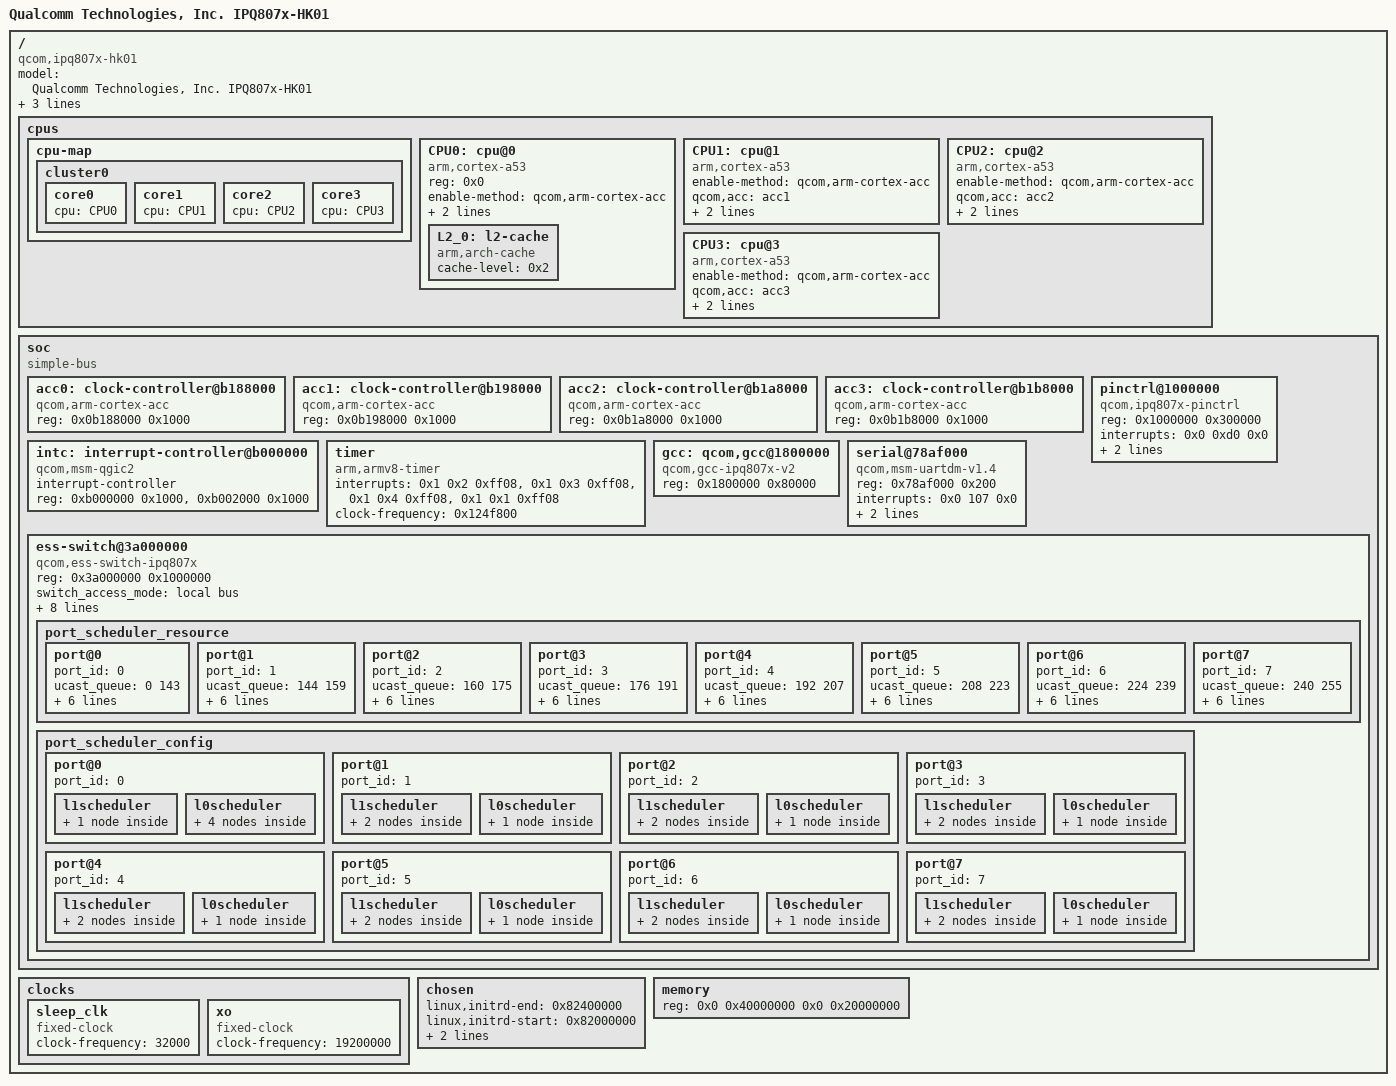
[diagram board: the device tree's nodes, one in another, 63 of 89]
/dts-v1/;
/*
 * Copyright (c) 2016-2018, The Linux Foundation. All rights reserved.
 *
 * Permission to use, copy, modify, and/or distribute this software for any
 * purpose with or without fee is hereby granted, provided that the above
 * copyright notice and this permission notice appear in all copies.
 *
 * THE SOFTWARE IS PROVIDED "AS IS" AND THE AUTHOR DISCLAIMS ALL WARRANTIES
 * WITH REGARD TO THIS SOFTWARE INCLUDING ALL IMPLIED WARRANTIES OF
 * MERCHANTABILITY AND FITNESS. IN NO EVENT SHALL THE AUTHOR BE LIABLE FOR
 * ANY SPECIAL, DIRECT, INDIRECT, OR CONSEQUENTIAL DAMAGES OR ANY DAMAGES
 * WHATSOEVER RESULTING FROM LOSS OF USE, DATA OR PROFITS, WHETHER IN AN
 * ACTION OF CONTRACT, NEGLIGENCE OR OTHER TORTIOUS ACTION, ARISING OUT OF
 * OR IN CONNECTION WITH THE USE OR PERFORMANCE OF THIS SOFTWARE.
 */

#include <dt-bindings/clock/qcom,gcc-ipq807x.h>
#include <dt-bindings/reset/qcom,gcc-ipq807x.h>

/ {
	#address-cells = <0x2>;
	#size-cells = <0x2>;
	model = "Qualcomm Technologies, Inc. IPQ807x-HK01";
	compatible = "qcom,ipq807x-hk01", "qcom,ipq807x";
	qcom,msm-id = <0x125 0x0>;
	interrupt-parent = <&intc>;
	qcom,board-id = <0x10 0x0>;

	cpus {
		#address-cells = <0x1>;
		#size-cells = <0x0>;

		cpu-map {

			cluster0 {

				core0 {
					cpu = <&CPU0>;
				};

				core1 {
					cpu = <&CPU1>;
				};

				core2 {
					cpu = <&CPU2>;
				};

				core3 {
					cpu = <&CPU3>;
				};
			};

		};

		 CPU0: cpu@0 {
			device_type = "cpu";
			compatible = "arm,cortex-a53";
			reg = <0x0>;
			enable-method = "qcom,arm-cortex-acc";
			qcom,acc = <&acc0>;
			next-level-cache = <&L2_0>;

			L2_0: l2-cache {
				compatible = "arm,arch-cache";
				cache-level = <0x2>;
			};
		};

		 CPU1: cpu@1 {
			device_type = "cpu";
			compatible = "arm,cortex-a53";
			enable-method = "qcom,arm-cortex-acc";
			qcom,acc = <&acc1>;
			reg = <0x1>;
			next-level-cache = <&L2_0>;
		};

		 CPU2: cpu@2 {
			device_type = "cpu";
			compatible = "arm,cortex-a53";
			enable-method = "qcom,arm-cortex-acc";
			qcom,acc = <&acc2>;
			reg = <0x2>;
			next-level-cache = <&L2_0>;
		};

		 CPU3: cpu@3 {
			device_type = "cpu";
			compatible = "arm,cortex-a53";
			enable-method = "qcom,arm-cortex-acc";
			qcom,acc = <&acc3>;
			reg = <0x3>;
			next-level-cache = <&L2_0>;
		};

	};

	soc: soc {
		#address-cells = <0x1>;
		#size-cells = <0x1>;
		ranges = <0 0 0 0xffffffff>;
		compatible = "simple-bus";

		acc0:clock-controller@b188000 {
			compatible = "qcom,arm-cortex-acc";
			reg = <0x0b188000 0x1000>;
		};

		acc1:clock-controller@b198000 {
			compatible = "qcom,arm-cortex-acc";
			reg = <0x0b198000 0x1000>;
		};

		acc2:clock-controller@b1a8000 {
			compatible = "qcom,arm-cortex-acc";
			reg = <0x0b1a8000 0x1000>;
		};

		acc3:clock-controller@b1b8000 {
			compatible = "qcom,arm-cortex-acc";
			reg = <0x0b1b8000 0x1000>;
		};

		pinctrl@1000000 {
			compatible = "qcom,ipq807x-pinctrl";
			reg = <0x1000000 0x300000>;
			interrupts = <0x0 0xd0 0x0>;
			gpio-controller;
			#gpio-cells = <0x2>;
			interrupt-controller;
			#interrupt-cells = <0x2>;
		};

		intc: interrupt-controller@b000000 {
			compatible = "qcom,msm-qgic2";
			interrupt-controller;
			#interrupt-cells = <0x3>;
			reg = <0xb000000 0x1000>,
			<0xb002000 0x1000>;
		};

		timer {
			compatible = "arm,armv8-timer";
			interrupts = <0x1 0x2 0xff08>,
				     <0x1 0x3 0xff08>,
				     <0x1 0x4 0xff08>,
				     <0x1 0x1 0xff08>;
			clock-frequency = <0x124f800>;
		};


		gcc: qcom,gcc@1800000 {
			compatible = "qcom,gcc-ipq807x-v2";
			reg = <0x1800000 0x80000>;
			#clock-cells = <0x1>;
			#reset-cells = <1>;
		};

		serial@78af000 {
			compatible = "qcom,msm-uartdm-v1.4", "qcom,msm-uartdm";
			reg = <0x78af000 0x200>;
			interrupts = <0x0 107 0x0>;
			status = "ok";
			clocks = <&gcc GCC_BLSP1_UART1_APPS_CLK>,
				 <&gcc GCC_BLSP1_AHB_CLK>;
			clock-names = "core", "iface";
		};

		ess-switch@3a000000 {
			compatible = "qcom,ess-switch-ipq807x";
			reg = <0x3a000000 0x1000000>;
			switch_access_mode = "local bus";
			switch_cpu_bmp = <0x1>;  /* cpu port bitmap */
			switch_lan_bmp = <0x3e>; /* lan port bitmap */
			switch_wan_bmp = <0x40>; /* wan port bitmap */
			switch_mac_mode = <0x0>; /* mac mode for uniphy 0*/
			switch_mac_mode1 = <0xff>; /* mac mode for uniphy 1*/
			switch_mac_mode2 = <0xd>; /* mac mode for uniphy 2*/
			bm_tick_mode = <0>; /* bm tick mode */
			tm_tick_mode = <0>; /* tm tick mode */
			port_scheduler_resource {
				port@0 {
					port_id = <0>;
					ucast_queue = <0 143>;
					mcast_queue = <256 271>;
					l0sp = <0 35>;
					l0cdrr = <0 47>;
					l0edrr = <0 47>;
					l1cdrr = <0 7>;
					l1edrr = <0 7>;
				};
				port@1 {
					port_id = <1>;
					ucast_queue = <144 159>;
					mcast_queue = <272 275>;
					l0sp = <36 39>;
					l0cdrr = <48 63>;
					l0edrr = <48 63>;
					l1cdrr = <8 11>;
					l1edrr = <8 11>;
				};
				port@2 {
					port_id = <2>;
					ucast_queue = <160 175>;
					mcast_queue = <276 279>;
					l0sp = <40 43>;
					l0cdrr = <64 79>;
					l0edrr = <64 79>;
					l1cdrr = <12 15>;
					l1edrr = <12 15>;
				};
				port@3 {
					port_id = <3>;
					ucast_queue = <176 191>;
					mcast_queue = <280 283>;
					l0sp = <44 47>;
					l0cdrr = <80 95>;
					l0edrr = <80 95>;
					l1cdrr = <16 19>;
					l1edrr = <16 19>;
				};
				port@4 {
					port_id = <4>;
					ucast_queue = <192 207>;
					mcast_queue = <284 287>;
					l0sp = <48 51>;
					l0cdrr = <96 111>;
					l0edrr = <96 111>;
					l1cdrr = <20 23>;
					l1edrr = <20 23>;
				};
				port@5 {
					port_id = <5>;
					ucast_queue = <208 223>;
					mcast_queue = <288 291>;
					l0sp = <52 55>;
					l0cdrr = <112 127>;
					l0edrr = <112 127>;
					l1cdrr = <24 27>;
					l1edrr = <24 27>;
				};
				port@6 {
					port_id = <6>;
					ucast_queue = <224 239>;
					mcast_queue = <292 295>;
					l0sp = <56 59>;
					l0cdrr = <128 143>;
					l0edrr = <128 143>;
					l1cdrr = <28 31>;
					l1edrr = <28 31>;
				};
				port@7 {
					port_id = <7>;
					ucast_queue = <240 255>;
					mcast_queue = <296 299>;
					l0sp = <60 63>;
					l0cdrr = <144 159>;
					l0edrr = <144 159>;
					l1cdrr = <32 35>;
					l1edrr = <32 35>;
				};
			};
			port_scheduler_config {
				port@0 {
					port_id = <0>;
					l1scheduler {
						group@0 {
							sp = <0 1>; /*L0 SPs*/
							/*cpri cdrr epri edrr*/
							cfg = <0 0 0 0>;
						};
					};
					l0scheduler {
						group@0 {
							/*unicast queues*/
							ucast_queue = <0 4 8>;
							/*multicast queues*/
							mcast_queue = <256 260>;
							/*sp cpricdrrepriedrr*/
							cfg = <0 0 0 0 0>;
						};
						group@1 {
							ucast_queue = <1 5 9>;
							mcast_queue = <257 261>;
							cfg = <0 1 1 1 1>;
						};
						group@2 {
							ucast_queue = <2 6 10>;
							mcast_queue = <258 262>;
							cfg = <0 2 2 2 2>;
						};
						group@3 {
							ucast_queue = <3 7 11>;
							mcast_queue = <259 263>;
							cfg = <0 3 3 3 3>;
						};
					};
				};
				port@1 {
					port_id = <1>;
					l1scheduler {
						group@0 {
							sp = <36>;
							cfg = <0 8 0 8>;
						};
						group@1 {
							sp = <37>;
							cfg = <1 9 1 9>;
						};
					};
					l0scheduler {
						group@0 {
							ucast_queue = <144>;
							ucast_loop_pri = <16>;
							mcast_queue = <272>;
							mcast_loop_pri = <4>;
							cfg = <36 0 48 0 48>;
						};
					};
				};
				port@2 {
					port_id = <2>;
					l1scheduler {
						group@0 {
							sp = <40>;
							cfg = <0 12 0 12>;
						};
						group@1 {
							sp = <41>;
							cfg = <1 13 1 13>;
						};
					};
					l0scheduler {
						group@0 {
							ucast_queue = <160>;
							ucast_loop_pri = <16>;
							mcast_queue = <276>;
							mcast_loop_pri = <4>;
							cfg = <40 0 64 0 64>;
						};
					};
				};
				port@3 {
					port_id = <3>;
					l1scheduler {
						group@0 {
							sp = <44>;
							cfg = <0 16 0 16>;
						};
						group@1 {
							sp = <45>;
							cfg = <1 17 1 17>;
						};
					};
					l0scheduler {
						group@0 {
							ucast_queue = <176>;
							ucast_loop_pri = <16>;
							mcast_queue = <280>;
							mcast_loop_pri = <4>;
							cfg = <44 0 80 0 80>;
						};
					};
				};
				port@4 {
					port_id = <4>;
					l1scheduler {
						group@0 {
							sp = <48>;
							cfg = <0 20 0 20>;
						};
						group@1 {
							sp = <49>;
							cfg = <1 21 1 21>;
						};
					};
					l0scheduler {
						group@0 {
							ucast_queue = <192>;
							ucast_loop_pri = <16>;
							mcast_queue = <284>;
							mcast_loop_pri = <4>;
							cfg = <48 0 96 0 96>;
						};
					};
				};
				port@5 {
					port_id = <5>;
					l1scheduler {
						group@0 {
							sp = <52>;
							cfg = <0 24 0 24>;
						};
						group@1 {
							sp = <53>;
							cfg = <1 25 1 25>;
						};
					};
					l0scheduler {
						group@0 {
							ucast_queue = <208>;
							ucast_loop_pri = <16>;
							mcast_queue = <288>;
							mcast_loop_pri = <4>;
							cfg = <52 0 112 0 112>;
						};
					};
				};
				port@6 {
					port_id = <6>;
					l1scheduler {
						group@0 {
							sp = <56>;
							cfg = <0 28 0 28>;
						};
						group@1 {
							sp = <57>;
							cfg = <1 29 1 29>;
						};
					};
					l0scheduler {
						group@0 {
							ucast_queue = <224>;
							ucast_loop_pri = <16>;
							mcast_queue = <292>;
							mcast_loop_pri = <4>;
							cfg = <56 0 128 0 128>;
						};
					};
				};
				port@7 {
					port_id = <7>;
					l1scheduler {
						group@0 {
							sp = <60>;
							cfg = <0 32 0 32>;
						};
						group@1 {
							sp = <61>;
							cfg = <1 33 1 33>;
						};
					};
					l0scheduler {
						group@0 {
							ucast_queue = <240>;
							ucast_loop_pri = <16>;
							mcast_queue = <296>;
							cfg = <60 0 144 0 144>;
						};
					};
				};
			};
		};

	};

	clocks {
		sleep_clk: sleep_clk {
			compatible = "fixed-clock";
			clock-frequency = <32000>;
			#clock-cells = <0>;
		};

		xo: xo {
			compatible = "fixed-clock";
			clock-frequency = <19200000>;
			#clock-cells = <0>;
		};
	};

	chosen {
		linux,initrd-end = <0x82400000>;
		linux,initrd-start = <0x82000000>;
		bootargs = "console=ttyMSM0,115200,n8 root=/dev/ram0 rw \
			    init=/init";
	};

	memory {
		device_type = "memory";
		reg = <0x0 0x40000000 0x0 0x20000000>;
	};

};

